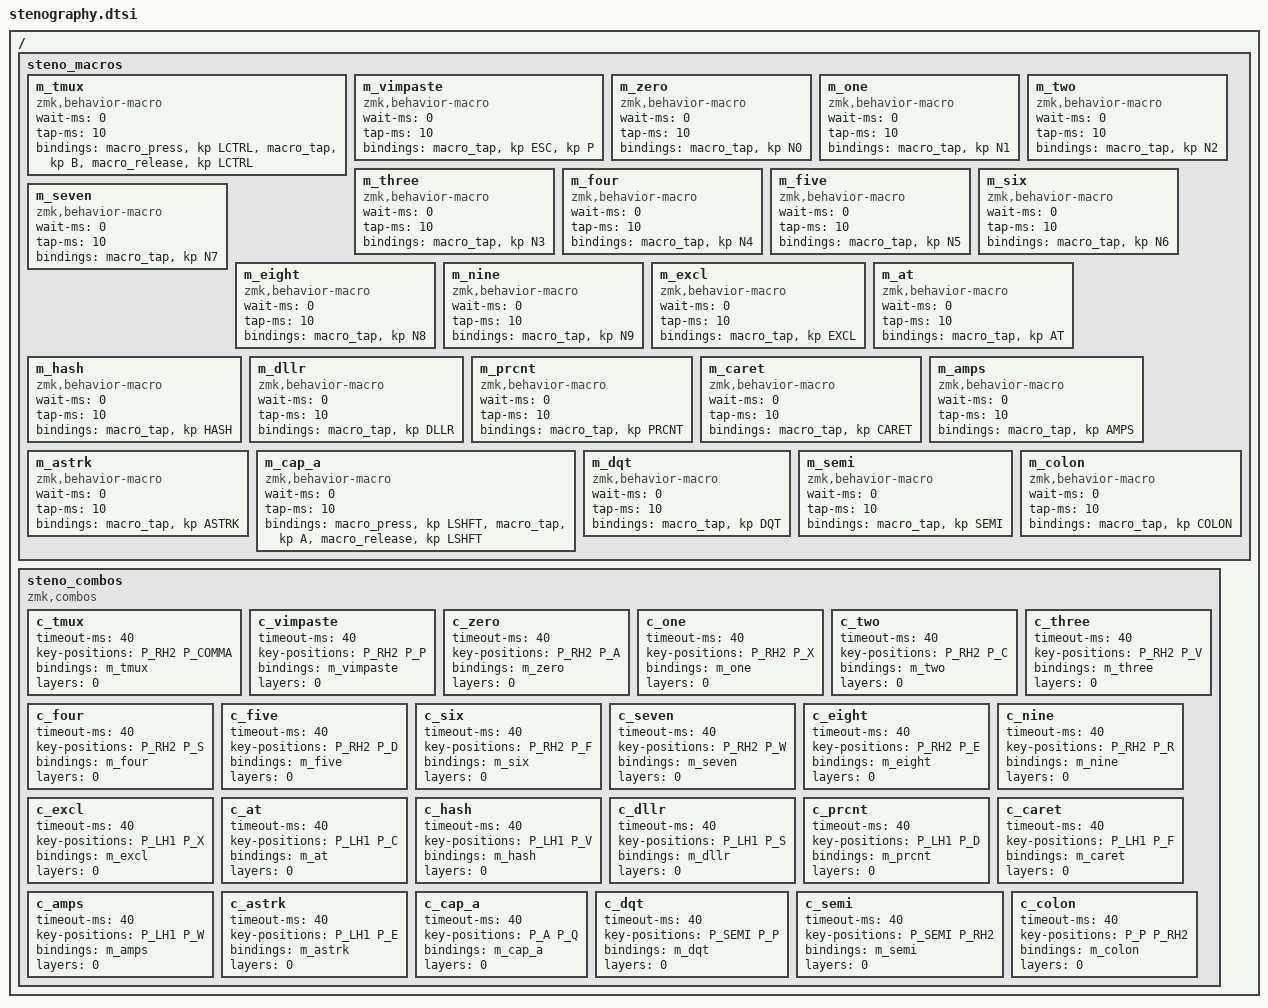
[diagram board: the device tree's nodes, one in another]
#include "keypos.h"

/ {
    steno_macros {
        m_tmux: m_tmux {
            compatible = "zmk,behavior-macro";
            #binding-cells = <0>;
            wait-ms = <0>;
            tap-ms = <10>;
            bindings = 
                <&macro_press &kp LCTRL>,
                <&macro_tap &kp B>,
                <&macro_release &kp LCTRL>;
        };

        m_vimpaste: m_vimpaste {
            compatible = "zmk,behavior-macro";
            #binding-cells = <0>;
            wait-ms = <0>;
            tap-ms = <10>;
            bindings = 
                <&macro_tap &kp ESC &kp P>;
        };

        m_zero: m_zero {
            compatible = "zmk,behavior-macro";
            #binding-cells = <0>;
            wait-ms = <0>;
            tap-ms = <10>;
            bindings = 
                <&macro_tap &kp N0>;
        };

        m_one: m_one {
            compatible = "zmk,behavior-macro";
            #binding-cells = <0>;
            wait-ms = <0>;
            tap-ms = <10>;
            bindings = 
                <&macro_tap &kp N1>;
        };

        m_two: m_two {
            compatible = "zmk,behavior-macro";
            #binding-cells = <0>;
            wait-ms = <0>;
            tap-ms = <10>;
            bindings = 
                <&macro_tap &kp N2>;
        };

        m_three: m_three {
            compatible = "zmk,behavior-macro";
            #binding-cells = <0>;
            wait-ms = <0>;
            tap-ms = <10>;
            bindings = 
                <&macro_tap &kp N3>;
        };

        m_four: m_four {
            compatible = "zmk,behavior-macro";
            #binding-cells = <0>;
            wait-ms = <0>;
            tap-ms = <10>;
            bindings = 
                <&macro_tap &kp N4>;
        };

        m_five: m_five {
            compatible = "zmk,behavior-macro";
            #binding-cells = <0>;
            wait-ms = <0>;
            tap-ms = <10>;
            bindings = 
                <&macro_tap &kp N5>;
        };

        m_six: m_six {
            compatible = "zmk,behavior-macro";
            #binding-cells = <0>;
            wait-ms = <0>;
            tap-ms = <10>;
            bindings = 
                <&macro_tap &kp N6>;
        };

        m_seven: m_seven {
            compatible = "zmk,behavior-macro";
            #binding-cells = <0>;
            wait-ms = <0>;
            tap-ms = <10>;
            bindings = 
                <&macro_tap &kp N7>;
        };

        m_eight: m_eight {
            compatible = "zmk,behavior-macro";
            #binding-cells = <0>;
            wait-ms = <0>;
            tap-ms = <10>;
            bindings = 
                <&macro_tap &kp N8>;
        };

        m_nine: m_nine {
            compatible = "zmk,behavior-macro";
            #binding-cells = <0>;
            wait-ms = <0>;
            tap-ms = <10>;
            bindings = 
                <&macro_tap &kp N9>;
        };

        m_excl: m_excl {
            compatible = "zmk,behavior-macro";
            #binding-cells = <0>;
            wait-ms = <0>;
            tap-ms = <10>;
            bindings =
                <&macro_tap &kp EXCL>;
        };

        m_at: m_at {
            compatible = "zmk,behavior-macro";
            #binding-cells = <0>;
            wait-ms = <0>;
            tap-ms = <10>;
            bindings =
                <&macro_tap &kp AT>;
        };

        m_hash: m_hash {
            compatible = "zmk,behavior-macro";
            #binding-cells = <0>;
            wait-ms = <0>;
            tap-ms = <10>;
            bindings =
                <&macro_tap &kp HASH>;
        };

        m_dllr: m_dllr {
            compatible = "zmk,behavior-macro";
            #binding-cells = <0>;
            wait-ms = <0>;
            tap-ms = <10>;
            bindings =
                <&macro_tap &kp DLLR>;
        };

        m_prcnt: m_prcnt {
            compatible = "zmk,behavior-macro";
            #binding-cells = <0>;
            wait-ms = <0>;
            tap-ms = <10>;
            bindings =
                <&macro_tap &kp PRCNT>;
        };

        m_caret: m_caret {
            compatible = "zmk,behavior-macro";
            #binding-cells = <0>;
            wait-ms = <0>;
            tap-ms = <10>;
            bindings =
                <&macro_tap &kp CARET>;
        };

        m_amps: m_amps {
            compatible = "zmk,behavior-macro";
            #binding-cells = <0>;
            wait-ms = <0>;
            tap-ms = <10>;
            bindings = 
                <&macro_tap &kp AMPS>;
        };

        m_astrk: m_astrk {
            compatible = "zmk,behavior-macro";
            #binding-cells = <0>;
            wait-ms = <0>;
            tap-ms = <10>;
            bindings = 
                <&macro_tap &kp ASTRK>;
        };

        m_cap_a: m_cap_a {
            compatible = "zmk,behavior-macro";
            #binding-cells = <0>;
            wait-ms = <0>;
            tap-ms = <10>;
            bindings = 
                <&macro_press &kp LSHFT>,
                <&macro_tap &kp A>,
                <&macro_release &kp LSHFT>;
        };

        m_dqt: m_dqt {
            compatible = "zmk,behavior-macro";
            #binding-cells = <0>;
            wait-ms = <0>;
            tap-ms = <10>;
            bindings = 
                <&macro_tap &kp DQT>;
        };

        m_semi: m_semi {
            compatible = "zmk,behavior-macro";
            #binding-cells = <0>;
            wait-ms = <0>;
            tap-ms = <10>;
            bindings = 
                <&macro_tap &kp SEMI>;
        };

        m_colon: m_colon {
            compatible = "zmk,behavior-macro";
            #binding-cells = <0>;
            wait-ms = <0>;
            tap-ms = <10>;
            bindings = 
                <&macro_tap &kp COLON>;
        };
    };

    steno_combos {
        compatible = "zmk,combos";
            c_tmux {
            timeout-ms = <40>;
            key-positions = <P_RH2 P_COMMA>;
            bindings = <&m_tmux>;
            layers = <0>;
        };

        compatible = "zmk,combos";
            c_vimpaste {
            timeout-ms = <40>;
            key-positions = <P_RH2 P_P>;
            bindings = <&m_vimpaste>;
            layers = <0>;
        };

        compatible = "zmk,combos";
            c_zero {
            timeout-ms = <40>;
            key-positions = <P_RH2 P_A>;
            bindings = <&m_zero>;
            layers = <0>;
        };

        compatible = "zmk,combos";
            c_one {
            timeout-ms = <40>;
            key-positions = <P_RH2 P_X>;
            bindings = <&m_one>;
            layers = <0>;
        };

        compatible = "zmk,combos";
            c_two {
            timeout-ms = <40>;
            key-positions = <P_RH2 P_C>;
            bindings = <&m_two>;
            layers = <0>;
        };

        compatible = "zmk,combos";
            c_three {
            timeout-ms = <40>;
            key-positions = <P_RH2 P_V>;
            bindings = <&m_three>;
            layers = <0>;
        };

        compatible = "zmk,combos";
            c_four {
            timeout-ms = <40>;
            key-positions = <P_RH2 P_S>;
            bindings = <&m_four>;
            layers = <0>;
        };

        compatible = "zmk,combos";
            c_five {
            timeout-ms = <40>;
            key-positions = <P_RH2 P_D>;
            bindings = <&m_five>;
            layers = <0>;
        };

        compatible = "zmk,combos";
            c_six {
            timeout-ms = <40>;
            key-positions = <P_RH2 P_F>;
            bindings = <&m_six>;
            layers = <0>;
        };

        compatible = "zmk,combos";
            c_seven {
            timeout-ms = <40>;
            key-positions = <P_RH2 P_W>;
            bindings = <&m_seven>;
            layers = <0>;
        };

        compatible = "zmk,combos";
            c_eight {
            timeout-ms = <40>;
            key-positions = <P_RH2 P_E>;
            bindings = <&m_eight>;
            layers = <0>;
        };

        compatible = "zmk,combos";
            c_nine {
            timeout-ms = <40>;
            key-positions = <P_RH2 P_R>;
            bindings = <&m_nine>;
            layers = <0>;
        };

        compatible = "zmk,combos";
            c_excl {
            timeout-ms = <40>;
            key-positions = <P_LH1 P_X>;
            bindings = <&m_excl>;
            layers = <0>;
        };

        compatible = "zmk,combos";
            c_at {
            timeout-ms = <40>;
            key-positions = <P_LH1 P_C>;
            bindings = <&m_at>;
            layers = <0>;
        };

        compatible = "zmk,combos";
            c_hash {
            timeout-ms = <40>;
            key-positions = <P_LH1 P_V>;
            bindings = <&m_hash>;
            layers = <0>;
        };

        compatible = "zmk,combos";
            c_dllr {
            timeout-ms = <40>;
            key-positions = <P_LH1 P_S>;
            bindings = <&m_dllr>;
            layers = <0>;
        };

        compatible = "zmk,combos";
            c_prcnt {
            timeout-ms = <40>;
            key-positions = <P_LH1 P_D>;
            bindings = <&m_prcnt>;
            layers = <0>;
        };

        compatible = "zmk,combos";
            c_caret {
            timeout-ms = <40>;
            key-positions = <P_LH1 P_F>;
            bindings = <&m_caret>;
            layers = <0>;
        };

        compatible = "zmk,combos";
            c_amps {
            timeout-ms = <40>;
            key-positions = <P_LH1 P_W>;
            bindings = <&m_amps>;
            layers = <0>;
        };

        compatible = "zmk,combos";
            c_astrk {
            timeout-ms = <40>;
            key-positions = <P_LH1 P_E>;
            bindings = <&m_astrk>;
            layers = <0>;
        };

        compatible = "zmk,combos";
            c_cap_a {
            timeout-ms = <40>;
            key-positions = <P_A P_Q>;
            bindings = <&m_cap_a>;
            layers = <0>;
        };

        compatible = "zmk,combos";
            c_dqt {
            timeout-ms = <40>;
            key-positions = <P_SEMI P_P>;
            bindings = <&m_dqt>;
            layers = <0>;
        };

        compatible = "zmk,combos";
            c_semi {
            timeout-ms = <40>;
            key-positions = <P_SEMI P_RH2>;
            bindings = <&m_semi>;
            layers = <0>;
        };

        compatible = "zmk,combos";
            c_colon {
            timeout-ms = <40>;
            key-positions = <P_P P_RH2>;
            bindings = <&m_colon>;
            layers = <0>;
        };
    };
};
